# SF32LB55x register map
File version: 1.0
CPU: CM33 r0p1, little endian, MPU, FPU, 3 interrupt priority bits
Registers are 32-bit, read-write, reset 0x0 unless marked. A register's access mark holds for its fields unless they carry their own. Offsets are from the block's base; [hi:lo] are bit positions; {n}, {i} and the like mark numbered series.

## SDMMC1
Base 0x50004000
Same registers: SDMMC2 0x50005000
0x00 SAR — System Address/Argument2 Register
  [31:0] ADDR — This register contains the physical system memory address used for DMA transfers or the second argument for the Auto CMD23. (1) SDMA System Address This register contains the system memory address for a SDMA transfer. The SDMA transfer waits at the every boundary specified by BSR_SDMABDY. After SDMA has stopped, the next system address of the next contiguous data position cannot be read from this register but from NSAR. The Host Controller generates ISR_DMA Interrupt to request the Host Driver to update this register. The Host Driver sets the next system address of the next data position to this register. When the most upper byte of this register is written, the Host Controller restarts the SDMA transfer. (2) Argument 2 This register is used with the Auto CMD23 to set a 32-bit block count value to the argument of the CMD23 while executing Auto CMD23. If Auto CMD23 is used with ADMA, the full 32-bit block count value can be used. If Auto CMD23 is used without AMDA, the available block count value is limited by BSR_BCNT. 65535 blocks is the maximum value in this case.
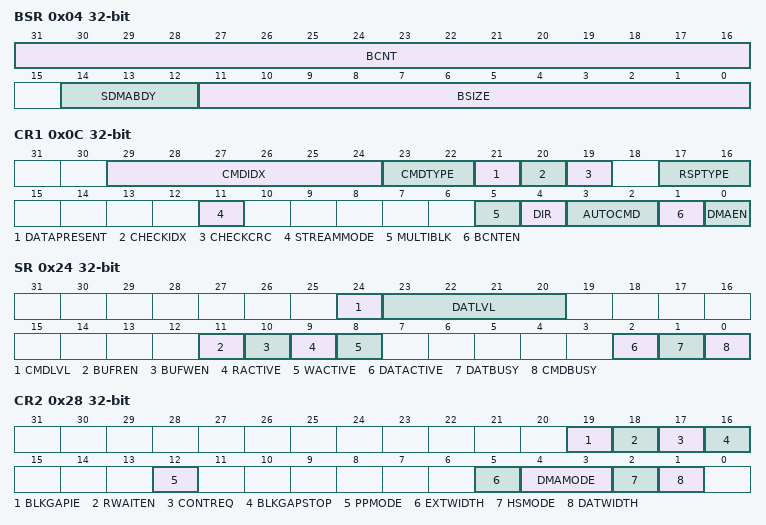
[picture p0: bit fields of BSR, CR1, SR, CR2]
0x04 BSR — Block Size Register
  [31:16] BCNT — Blocks Count For Current Transfer. This register is enabled when MULTIBLK is set to 1 and is valid only for multiple block transfers. Controller decrements the block count after each block transfer. Setting the block count to 0 results in no data blocks is transferred. This register should be accessed only when no transaction is executing (i.e., after transactions are stopped). During data transfer, read operations on this register may return an invalid value and write operations are ignored. When a suspend command is completed, the number of blocks yet to be transferred can be determined by reading this register. Before issuing a resume command, the Host Driver shall restore the previously saved block count. FFFFh 65535 blocks ... ... 0002h 2 blocks 0001h 1 block 0000h Stop Count
  [14:12] SDMABDY — Host SDMA Buffer Boundary. The large contiguous memory space may not be available in the virtual memory system. To perform long SDMA transfer, SDMA System Address register shall be updated at every system memory boundary during SDMA transfer. These bits specify the size of contiguous buffer in the system memory. The SDMA transfer shall wait at the every boundary specified by these fields and the Controller generates the ISR_DMA Interrupt to request the Host Driver to update the SDMA System Address register. At the end of transfer, the Controller may issue or may not issue ISR_DMA Interrupt. In particular, ISR_DMA Interrupt shall not be issued after ISR_TC Interrupt is issued. In case of this register is set to 0 (buffer size = 4K bytes), lower 12-bit of byte address points data in the contiguous buffer and the upper 20-bit points the location of the buffer in the system memory. The SDMA transfer stops when the Controller detects carry out of the address from bit 11 to 12. ADMA does not use this register. 000b 4K bytes (Detects A11 carry out) 001b 8K bytes (Detects A12 carry out) 010b 16K Bytes (Detects A13 carry out) 011b 32K Bytes (Detects A14 carry out) 100b 64K bytes (Detects A15 carry out) 101b 128K Bytes (Detects A16 carry out) 110b 256K Bytes (Detects A17 carry out) 111b 512K Bytes (Detects A18 carry out)
  [11:0] BSIZE — Transfer Block Size This register specifies the block size of data transfers such as CMD17, CMD18, CMD24, CMD25, and CMD53. Usually set to 512 for SD and eMMC access.
0x08 ARG1 — Argument 1
  [31:0] ARG — Command Argument 1 The SD command argument is specified as bit39-8 of Command-Format in the Physical Layer Specification.
0x0C CR1 — Control and Command Register 1
  [29:24] CMDIDX — Command Index These bits shall be set to the command number (CMD0-63, ACMD0-63) that is specified in bits 45-40 of the Command-Format in the Physical Layer Specification and SDIO Card Specification.
  [23:22] CMDTYPE — Command Type There are three types of special commands: Suspend, Resume and Abort. These bits shall be set to 00b for all other commands. (1) Suspend Command If the Suspend command succeeds, the Controller shall assume the SD Bus has been released and that it is possible to issue the next command, which uses the DAT line. The Controller shall de-assert Read Wait for read transactions and stop checking busy for write transactions. The interrupt cycle shall start, in 4-bit mode. If the Suspend command fails, the Controller shall maintain its current state, and the Host Driver shall restart the transfer by setting CR2_CONTREQ. (2) Resume Command The Host Driver re-starts the data transfer. The Controller shall check for busy before starting write transfers. (3) Abort Command If this command is set when executing a read transfer, the Controller shall stop reads to the buffer. If this command is set when executing a write transfer, the Controller shall stop driving the DAT line. After issuing the Abort command, the Host Driver should issue a software reset. 11b Abort CMD12, CMD52 for writing "I/O Abort" in CCCR 10b Resume CMD52 for writing "Function Select" in CCCR 01b Suspend CMD52 for writing "Bus Suspend" in CCCR 00b Normal Other commands
  [21] DATAPRESENT — Data Present Select This bit is set to 1 to indicate that data is present and shall be transferred using the DAT line. It is set to 0 for the following: (1) Commands using only CMD line (ex. CMD52). (2) Commands with no data transfer but using busy signal on DAT[0] line (R1b or R5b ex. CMD38) (3) Resume command
  [20] CHECKIDX — Command Index Check Enable If this bit is set to 1, the Controller shall check the Index field in the response to see if it has the same value as the command index. If it is not, it is reported as a Command Index Error. If this bit is set to 0, the Index field is not checked.
  [19] CHECKCRC — Command CRC Check Enable If this bit is set to 1, the Controller shall check the CRC field in the response. If an error is detected, it is reported as a Command CRC Error. If this bit is set to 0, the CRC field is not checked. The position of CRC field is determined according to the length of the response.
  [17:16] RSPTYPE — Response Type Select 00 No Response 01 Response Length 136 10 Response Length 48 11 Response Length 48 check Busy after
  [11] STREAMMODE — Stream Mode Enable The Host driver has to set this bit for MMC CMD11 / CMD20 Stream Read/Write Operations.
  [5] MULTIBLK — Multi / Single Block Select This bit is set when issuing multiple-block transfer commands using DAT line. For any other commands, this bit shall be set to 0. If this bit is 0, it is not necessary to set BSR_BCNT
  [4] DIR — Data Transfer Direction Select This bit defines the direction of DAT line data transfers. The bit is set to 1 to read data from the SD card to the Controller and it is set to 0 for all other commands. 1 Read (Card to Host) 0 Write (Host to Card)
  [3:2] AUTOCMD — Auto CMD Enable This field determines use of auto command functions. 00b Auto Command Disabled 01b Auto CMD12 Enabled 10b Auto CMD23 Enabled 11b Reserved There are two methods to stop Multiple-block read and write operation. (1) Auto CMD12 Enable When this field is set to 01b, the Controller issues CMD12 automatically when last block transfer is completed. Auto CMD12 error is indicated to CR4. The Host Driver shall not set this bit if the command does not require CMD12. (2) Auto CMD23 Enable When this bit field is set to 10b, the Controller issues a CMD23 automatically before issuing a command specified. The following conditions are required to use the Auto CMD23. A memory card that supports CMD23 (SCR[33]=1) If DMA is used, it shall be ADMA. Only when CMD18 or CMD25 is issued (Note, the Controller does not check command index.) Auto CMD23 can be used with or without ADMA. The Controller issues a CMD23 first and then issues a command specified by CR1. If response errors of CMD23 are detected, the second command is not issued. A CMD23 error is indicated in CR4. 32-bit block count value for CMD23 is set to SAR.
  [1] BCNTEN — Block Count Enable This bit is used to enable the Block Count register, which is only relevant for multiple block transfers. When this bit is 0, the Block Count register is disabled, which is useful in executing an infinite transfer. If ADMA data transfer is more than 65535 blocks, this bit shall be set to 0. In this case, data transfer length is designated by Descriptor Table.
  [0] DMAEN — DMA Enable This bit enables DMA functionality. SDMA or ADMA mode can be selected by CR2_DMAMODE.
0x10 RSP1 — Command Response 31~0
  [31:0] RSP — Command Response [31:0] The Response Field indicates bit positions of "Responses" defined in the Physical Layer Spec. Most responses with a length of 48 (R[47:0]) have 32 bits of the response data (R[39:8]) stored in RSP1. Responses of type R1b (Auto CMD12 responses) and R1 (Auto CMD23 response) have response data bits R[39:8] stored in RSP4. Responses with length 136 (R[135:0]) have 120 bits of the response data (R[127:8]) stored in RSP1~RSP4. To be able to read the response status efficiently, the Controller only stores part of the response data. This enables the Host Driver to read 32 bits of response data efficiently in one read cycle on a 32-bit bus system. Parts of the response, the Index field and the CRC, are checked by the Controller (as specified by CR1_CHECKIDX and the CR1_CHECKCRC) and generate an error interrupt if an error is detected. The bit range for the CRC check depends on the response length. If the response length is 48, the Controller shall check R[47:1], and if the response length is 136 the Controller shall check R[119:1]. Since the Controller may have a multiple block data DAT line transfer executing concurrently with a CMD_wo_DAT command, the Controller stores the Auto CMD12 response in RSP4. The CMD_wo_DAT response is stored in RSP1. This allows the Controller to avoid overwriting the Auto CMD12 response with the CMD_wo_DAT and vice versa. While executing Auto CMD23, the response of CMD23 is saved to RSP4 and the response of multiple-block read and write command is save to RSP1. The response error of CMD23 is indicated in CR4.
{0xC+4i} RSP{i} (i=2..4) — Command Response {32i-1}~{32i-32}
  [31:0] RSP — Command Response [{32i-1}:{32i-32}]
0x20 BUF — Buffer Data Port Register
  [31:0] DATA — Buffer Data The Controller buffer can be accessed through this 32-bit Data Port register.
0x24 SR — Present State Register
  [24] CMDLVL — CMD Line Signal Level This status is used to check the CMD line level to recover from errors, and for debugging.
  [23:20] DATLVL — DAT-DAT3 Line Signal Level This status is used to check the DAT line level to recover from errors, and for debugging. This is especially useful in detecting the busy signal level from DAT [0].
  [11] BUFREN — Buffer Read Enable This status is used for non-DMA read transfers. The Controller may implement multiple buffers to transfer data efficiently. This read only flag indicates that valid data exists in the host side buffer. If this bit is 1, readable data exists in the buffer. A change of this bit from 1 to 0 occurs when all the block data is read from the buffer. A change of this bit from 0 to 1 occurs when block data is ready in the buffer and generates ISR_BUFRRDY.
  [10] BUFWEN — Buffer Write Enable This status is used for non-DMA write transfers. The Controller can implement multiple buffers to transfer data efficiently. This read only flag indicates if space is available for write data. If this bit is 1, data can be written to the buffer. A change of this bit from 1 to 0 occurs when all the block data is written to the buffer. A change of this bit from 0 to 1 occurs when top of block data can be written to the buffer and generates ISR_BUFWRDY. The Controller should neither set Buffer Write Enable nor generate ISR_BUFWRDY after the last block data is written to the Buffer Data Port Register.
  [9] RACTIVE — Read Transfer Active This status is used for detecting completion of a read transfer. This bit is set to 1 for either of the following conditions: (1) After the end bit of the readcommand. (2) When read operation is restarted by writing 1 to CR2_CONTREQ. This bit is cleared to 0 for either of the following conditions: (1) When the last data block as specified by block length is transferred to the System. (2) In case of ADMA, end of read operation is designated by Descriptor Table. (3) When all valid data blocks in the Controller have been transferred to the System and no current block transfers are being sent as a result of CR2_BLKGAPSTOP being set to 1. A Transfer Complete interrupt is generated when this bit changes to 0.
  [8] WACTIVE — Write Transfer Active This status indicates a write transfer is active. If this bit is 0, it means no valid write data exists in the Controller. This bit is set in either of the following cases:  After the end bit of the write command.  When write operation is restarted by writing 1 to CR2_CONTREQ. This bit is cleared in either of the following cases:  After getting the CRC status of the last data block as specified by the transfer count (Single and Multiple) In case of ADMA, transfer count is designated by Descriptor Table.  After getting the CRC status of any block where data transmission is about to be stopped by CR2_BLKGAPSTOP. During a write transaction, ISR_BLKGAP is generated when this bit is changed to 0, as the result of CR2_BLKGAPSTOP begin set. This status is useful for the Host Driver in determining non DAT line commands can be issued during write busy.
  [2] DATACTIVE — DAT Line Active This bit indicates whether one of the DAT line on SD Bus is in use. (a) In the case of read transactions This status indicates whether a read transfer is executing on the SD Bus. Changing this value from 1 to 0 generates ISR_BLKGAP, as the result of CR2_BLKGAPSTOP being set. This bit shall be set in either of the following cases: (1) After the end bit of the read command. (2) When writing 1 to CR2_CONTREQ to restart a read transfer. This bit shall be cleared in either of the following cases (1) When the end bit of the last data block is sent from the SD Bus to the Controller. In case of ADMA, the last block is designated by the last transfer of Descriptor Table. (2) When a read transfer is stopped at the block gap initiated by CR2_BLKGAPSTOP. The Controller shall stop read operation at the start of the interrupt cycle of the next block gap by driving Read Wait or stopping SD clock. If the Read Wait signal is already driven (due to data buffer cannot receive data), the Controller can continue to stop read operation by driving the Read Wait signal. It is necessary to support Read Wait in order to use suspend / resume function. (b) In the case of write transactions This status indicates that a write transfer is executing on the SD Bus. Changing this value from 1 to 0 generate ISR_TC. This bit shall be set in either of the following cases: (1) After the end bit of the write command. (2) When writing 1 to CR2_CONTREQ to continue a write transfer. This bit shall be cleared in either of the following cases: (1) When the SD card releases write busy of the last data block. If SD card does not drive busy signal for 8 SD Clocks, the Controller shall consider the card drive "Not Busy". In case of ADMA, the last block is designated by the last transfer of Descriptor Table. (2) When the SD card releases write busy prior to waiting for write transfer as a result of CR2_BLKGAPSTOP. (c) Command with busy This status indicates whether a command indicates busy (ex. erase command for memory) is executing on the SD Bus. This bit is set after the end bit of the command with busy and cleared when busy is de-asserted. Changing this bit from 1 to 0 generate ISR_TC.
  [1] DATBUSY — Command Inhibit (DAT) This status bit is generated if either the DAT Line Active or the Read Transfer Active is set to 1. If this bit is 0, it indicates the Controller can issue the next SD Command. Commands with busy signal belong to Command Inhibit (DAT) (ex. R1b, R5b type). Changing from 1 to 0 generates ISR_TC interrupt. 1 Cannot issue command which uses the DAT line 0 Can issue command which uses the DAT line
  [0] CMDBUSY — Command Inhibit (CMD) If this bit is 0, it indicates the CMD line is not in use and the Controller can issue a SD Command using the CMD line. This bit is set immediately after CR1 is written. This bit is cleared when the command response is received. Auto CMD12 and Auto CMD23 consist of two responses. In this case, this bit is not cleared by the response of CMD12 or CMD23 but cleared by the response of a read/write command. Status issuing Auto CMD12 is not read from this bit. So if a command is issued during Auto CMD12 operation, Controller shall manage to issue two commands: CMD12 and a command set by CR1. Even if the DATBUSY is set to 1, commands using only the CMD line can be issued if this bit is 0. Changing from 1 to 0 generates ISR_CC Interrupt. If the Controller cannot issue the command because of a command conflict error or because of Command Not Issued By Auto CMD12 Error, this bit shall remain 1 and the Command Complete is not set. 1 Cannot issue command 0 Can issue command using only CMD line
0x28 CR2 — Control Register 2
  [19] BLKGAPIE — Interrupt At Block Gap This bit is valid only in 4-bit mode of the SDIO card and selects a sample point in the interrupt cycle. Setting to 1 enables interrupt detection at the block gap for a multiple block transfer. Setting to 0 disables interrupt detection during a multiple block transfer. If the SD card cannot signal an interrupt during a multiple block transfer, this bit should be set to 0. The Host Driver shall set this bit according to the CCCR of the SDIO card.
  [18] RWAITEN — Read Wait Control The read wait function is optional for SDIO cards. If the card supports read wait, set this bit to enable use of the read wait protocol to stop read data using the DAT2 line. Otherwise, the Controller has to stop the SD Clock to hold read data, which restricts commands generation. The Host Driver shall set this bit according to the CCCR of the SDIO card. If the card does not support read wait, this bit shall never be set to 1 otherwise DAT line conflict may occur. If this bit is set to 0, Suspend/Resume cannot be supported.
  [17] CONTREQ — Continue Request
  [16] BLKGAPSTOP — Stop At Block Gap request This bit is used to stop executing read and write transaction at the next block gap for non-DMA, SDMA and ADMA transfers. The Host Driver shall leave this bit set to 1 until the Transfer Complete is set to 1. Clearing both Stop At Block Gap Request and Continue Request shall not cause the transaction to restart. The Controller shall stop read transfer by using Read Wait or stopping SD clock. In case of write transfers in which the Host Driver writes data to the Buffer Data Port register, the Host Driver shall set this bit after all block data is written. If this bit is set to 1, the Host Driver shall not write data to BUF. 1 Stop 0 Transfer
  [12] PPMODE — CMD line output mode. Open drain mode should only be used when accessing eMMC device. 1 Push Pull Mode 0 Open Drain Mode
  [5] EXTWIDTH — Extended Data Transfer Width 1 8-bit Bus Width 0 Bus Width is Selected by DATAWIDTH
  [4:3] DMAMODE — DMA Select One of supported DMA modes can be selected. DMA mode is enabled by CR1_DMAEN. 00b SDMA 01b Reserved 10b ADMA 11b Reserved
  [2] HSMODE — Reserved for debug. Adjust output timing of CMD line and DAT lines.
  [1] DATWIDTH — Data Transfer Width This bit selects the data width of the Controller when EXTWIDTH is 0. The Host Driver shall set it to match the data width of the SD card. 1 4-bit mode 0 1-bit mode
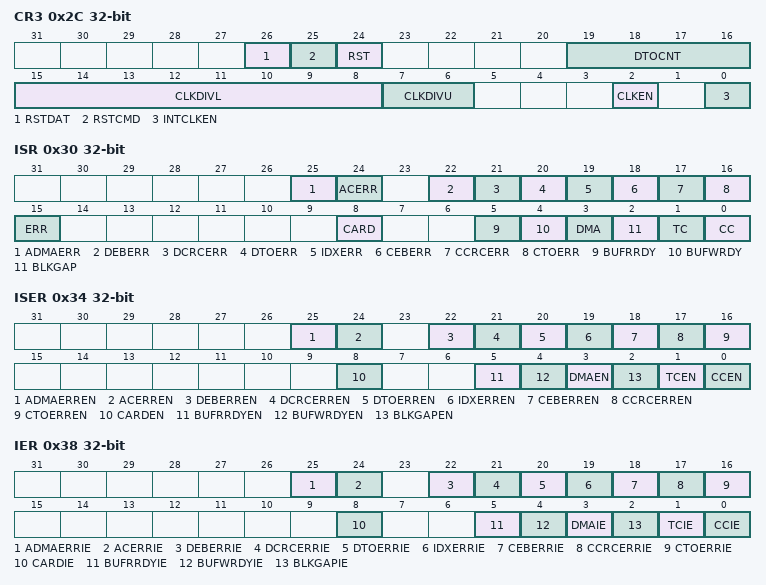
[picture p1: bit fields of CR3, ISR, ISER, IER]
0x2C CR3 — Control Register 3
  [26] RSTDAT — Software Reset For DAT Line Only part of data circuit is reset. DMA circuit is also reset. Will be cleared automatically. Because it takes some time to complete software reset, the SD Host Driver shall confirm that these bits are 0.
  [25] RSTCMD — Software Reset For CMD Line Only part of command circuit is reset. Will be cleared automatically. Because it takes some time to complete software reset, the SD Host Driver shall confirm that these bits are 0.
  [24] RST — This reset affects the entire Controller except for the card detection circuit. Register bits (except read-only bits) are cleared to 0. During its initialization, the Host Driver shall set this bit to 1 to reset the Controller. If this bit is set to 1, the host driver should issue reset command and reinitialize the SD card. Will be cleared automatically. Because it takes some time to complete software reset, the SD Host Driver shall confirm that these bits are 0.
  [19:16] DTOCNT — Data Timeout Counter Value This value determines the interval by which DAT line timeouts are detected. Timeout period is defined as: 1111b Reserved 1110b 4096*2^14 FCLK periods ............ ............ 0001b 4096*2^1 FCLK periods 0000b 4096*2 FCLK periods
  [15:8] CLKDIVL — CLK divider lower 8 bits 10-bit CLKDIV is {CLKDIVU,CLKDIVL}. If CLKDIV=0, CLK = FCLK. If CLKDIV!=0, CLK = FCLK/(2*CLKDIV). e.g. FCLK=192MHz, CLKDIV=240, then CLK frequency is 400KHz.
  [7:6] CLKDIVU — CLK divider upper 2 bits These bits expand clk divider to 10-bit.
  [2] CLKEN — SD Clock Enable 0: SD clock disabled 1: SD clock enabled
  [0] INTCLKEN — Internal Clock Enable 0: Internal clock disabled 1: Internal clock enabled
0x30 ISR — Interrupt State Register
  [25] ADMAERR — ADMA Error This bit is set when the Controller detects errors during ADMA based data transfer. The state of the ADMA at an error occurrence is saved in the AESR, In addition, the Controller generates this Interrupt when it detects invalid descriptor data (Valid=0). ADMA Error State in the ADMA Error Status indicates that an error occurs. The Host Driver may find that Valid bit is not set at the error descriptor.
  [24] ACERR — Auto CMD Error Auto CMD12 and Auto CMD23 use this error status. In case of Auto CMD12, this bit is set to 1, not only when the errors in Auto CMD12 occur but also when Auto CMD12 is not executed due to the previous command error.
  [22] DEBERR — Data End Bit Error Occurs either when detecting 0 at the end bit position of read data which uses the DAT line or at the end bit position of the CRC Status.
  [21] DCRCERR — Data CRC Error Occurs when detecting CRC error when transferring read data which uses the DAT line or when detecting the Write CRC status having a value of other than "010".
  [20] DTOERR — Data Timeout Error This bit is set when detecting one of following timeout conditions.  Busy timeout for R1b,R5b type  Busy timeout after Write CRC status  Write CRC Status timeout  Read Data timeout.
  [19] IDXERR — Command Index Error This bit is set if a Command Index error occurs in the command response.
  [18] CEBERR — Command End Bit Error This bit is set when detecting that the end bit of a command response is 0.
  [17] CCRCERR — Command CRC Error Command CRC Error is generated in two cases. If a response is returned and the Command Timeout Error is set to 0 (indicating no timeout), this bit is set to 1 when detecting a CRC error in the command response. The Controller detects a CMD line conflict by monitoring the CMD line when a command is issued. If the Controller drives the CMD line to 1 level, but detects 0 level on the CMD line at the next SD clock edge, then the Controller shall abort the command (Stop driving CMD line) and set this bit to 1. The Command Timeout Error shall also be set to 1 to distinguish CMD line conflict
  [16] CTOERR — Command Timeout Error This bit is set only if no response is returned within 64 SD clock cycles from the end bit of the command. If the Controller detects a CMD line conflict, in which case Command CRC Error shall also be set, this bit shall be set without waiting for 64 SD clock cycles because the command will be aborted by the Controller.
  [15] ERR — Error Interrupt If any error bit (bit16~bit31) of ISR are set, then this bit is set. Therefore the Host Driver can efficiently test for an error by checking this bit first. This bit is read only.
  [8] CARD — Card Interrupt Writing this bit to 1 does not clear this bit. It is cleared by resetting the SD card interrupt factor. In 4-bit mode, the card interrupt signal is sampled during the interrupt cycle, so there are some sample delays between the interrupt signal from the SD card and the interrupt to the Host System. When this status has been set and the Host Driver needs to start this interrupt service, ISER_CARDEN may be set to 0 in order to clear the card interrupt statuses latched in the Controller and to stop driving the interrupt signal to the Host System. After completion of the card interrupt service (It should reset interrupt factors in the SD card and the interrupt signal may not be asserted), set ISER_CARDEN to 1 and start sampling the interrupt signal again.
  [5] BUFRRDY — Buffer Read Ready This status is set if the Buffer Read Enable changes from 0 to 1. Refer to SR_BUFREN register. 1 Ready to read buffer 0 Not ready to read buffer
  [4] BUFWRDY — Buffer Write Ready This status is set if the Buffer Write Enable changes from 0 to 1. Refer to SR_BUFWEN register. 1 Ready to write buffer 0 Not ready to write buffer
  [3] DMA — DMA Interrupt This status is set if the Controller detects the Host SDMA Buffer boundary during transfer. Refer to BSR_SDMABDY. In case of ADMA, by setting INT field in the descriptor table, Controller generates this interrupt. This interrupt shall not be generated after the Transfer Complete.
  [2] BLKGAP — Block Gap Event If CR2_BLKGAPSTOP is set, this bit is set when both a read / write transaction is stopped at a block gap. If CR2_BLKGAPSTOP is not set to 1, this bit is not set to 1. (1) In the case of a Read Transaction This bit is set at the falling edge of the DAT Line Active Status (When the transaction is stopped at SD Bus timing. The Read Wait shall be supported in order to use this function. (2) Case of Write Transaction This bit is set at the falling edge of Write Transfer Active Status (After getting CRC status at SD Bus timing). 1 Transaction stopped at block 0 No Block Gap Event
  [1] TC — Transfer Complete This bit is set when a read / write transfer and a command with busy is completed. (1) In the case of a Read Transaction This bit is set at the falling edge of Read Transfer Active Status. This interrupt is generated in two cases. The first is when a data transfer is completed as specified by data length (After the last data has been read to the Host System). The second is when data has stopped at the block gap and completed the data transfer by setting CR2_BLKGAPSTOP (After valid data has been read to the Host System). (2) In the case of a Write Transaction This bit is set at the falling edge of the DAT Line Active Status. This interrupt is generated in two cases. The first is when the last data is written to the SD card as specified by data length and the busy signal released. The second is when data transfers are stopped at the block gap by setting CR2_BLKGAPSTOP and data transfers completed. (After valid data is written to the SD card and the busy signal released). (3) In the case of a command with busy This bit is set when busy is de-asserted. Refer to SR_DATACTIVE and SR_CMDBUSY. Transfer Complete has higher priority than Data Timeout Error. If both bits are set to 1, execution of a command can be considered to be completed.
  [0] CC — Command Complete This bit is set when get the end bit of the command response. Auto CMD12 and Auto CMD23 consist of two responses. Command Complete is not generated by the response of CMD12 or CMD23 but generated by the response of a read/write command. Command Timeout Error has higher priority than Command Complete. If both bits are set to 1, it can be considered that the response was not received correctly.
0x34 ISER — Interrupt Status Enable Register
  [25] ADMAERREN — ADMA Error Status Enable
  [24] ACERREN — Auto CMD Error Status Enable
  [22] DEBERREN — Data End Bit Error Status Enable
  [21] DCRCERREN — Data CRC Error Status Enable
  [20] DTOERREN — Data Timeout Error Status Enable
  [19] IDXERREN — Command Index Error Status Enable
  [18] CEBERREN — Command End Bit Error Status Enable
  [17] CCRCERREN — Command CRC Error Status Enable
  [16] CTOERREN — Command Timeout Error Status Enable
  [8] CARDEN — Card Interrupt Status Enable If this bit is set to 0, the Controller shall clear interrupt request to the System. The Card Interrupt detection is stopped when this bit is cleared and restarted when this bit is set to 1. The Host Driver may clear the Card Interrupt Status Enable before servicing the Card Interrupt and may set this bit again after all interrupt requests from the card are cleared to prevent inadvertent interrupts.
  [5] BUFRRDYEN — Buffer Read Ready Status Enable
  [4] BUFWRDYEN — Buffer Write Ready Status Enable
  [3] DMAEN — DMA Interrupt Status Enable
  [2] BLKGAPEN — Block Gap Event Status Enable
  [1] TCEN — Transfer Complete Status Enable
  [0] CCEN — Command Complete Status Enable
0x38 IER — Interrupt Enable Register
  [25] ADMAERRIE — ADMA Error Interrupt Enable
  [24] ACERRIE — Auto CMD Error Interrupt Enable
  [22] DEBERRIE — Data End Bit Error Interrupt Enable
  [21] DCRCERRIE — Data CRC Error Interrupt Enable
  [20] DTOERRIE — Data Timeout Error Interrupt Enable
  [19] IDXERRIE — Command Index Error Interrupt Enable
  [18] CEBERRIE — Command End Bit Error Interrupt Enable
  [17] CCRCERRIE — Command CRC Error Interrupt Enable
  [16] CTOERRIE — Command Timeout Error Interrupt Enable
  [8] CARDIE — Card Interrupt Interrupt Enable If this bit is set to 0, the Controller shall clear interrupt request to the System. The Card Interrupt detection is stopped when this bit is cleared and restarted when this bit is set to 1. The Host Driver may clear the Card Interrupt Status Enable before servicing the Card Interrupt and may set this bit again after all interrupt requests from the card are cleared to prevent inadvertent interrupts.
  [5] BUFRRDYIE — Buffer Read Ready Interrupt Enable
  [4] BUFWRDYIE — Buffer Write Ready Interrupt Enable
  [3] DMAIE — DMA Interrupt Interrupt Enable
  [2] BLKGAPIE — Block Gap Event Interrupt Enable
  [1] TCIE — Transfer Complete Interrupt Enable
  [0] CCIE — Command Complete Interrupt Enable
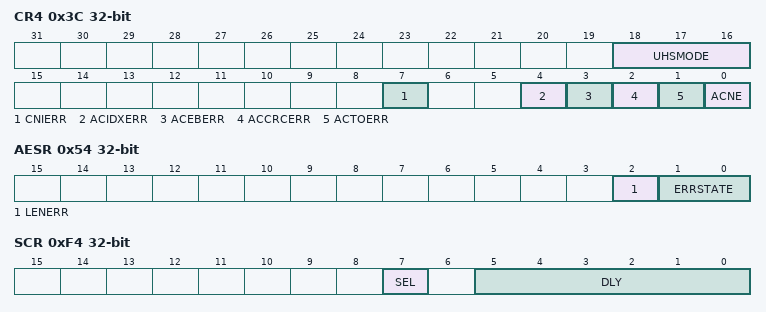
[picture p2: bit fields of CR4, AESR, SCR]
0x3C CR4 — Control Register 4
  [18:16] UHSMODE — UHS Mode Select 100b DDR others SDR
  [7] CNIERR — Command Not Issued By Auto CMD12 Error Setting this bit to 1 means CMD_wo_DAT is not executed due to an Auto CMD12 Error in this register. This bit is set to 0 when Auto CMD Error is generated by Auto CMD23. 1 Not Issued 0 No Error
  [4] ACIDXERR — Auto CMD Index Error This bit is set if the Command Index error occurs in response to a command
  [3] ACEBERR — Auto CMD End Bit Error This bit is set when detecting that the end bit of command response is 0.
  [2] ACCRCERR — Auto CMD CRC Error This bit is set when detecting a CRC error in the command response.
  [1] ACTOERR — Auto CMD Timeout Error This bit is set if no response is returned within 64 SDCLK cycles from the end bit of command. If this bit is set to1, the other error status bits are meaningless.
  [0] ACNE — Auto CMD12 Not Executed If memory multiple block data transfer is not started due to command error, this bit is not set because it is not necessary to issue Auto CMD12. Setting this bit to 1 means the Controller cannot issue Auto CMD12 to stop memory multiple block data transfer due to some error. If this bit is set to 1, other error status bits are meaningless. This bit is set to 0 when Auto CMD Error is generated by Auto CMD23. 1 Not Executed 0 Executed
0x54 AESR — ADMA Error Status Register
  [2] LENERR — ADMA Length Mismatch Error This error occurs in the following 2 cases. (1) While CR1_BCNTEN being set, the total data length specified by the Descriptor table is different from that specified by the Block Count and Block Length. (2) Total data length cannot be divided by the block length.
  [1:0] ERRSTATE — ADMA Error State This field indicates the state of ADMA when error is occurred during ADMA data transfer. This field never indicates "10" because ADMA never stops in this state. 00 ST_STOP (Stop DMA) Points next of the error descriptor 01 ST_FDS (Fetch Descriptor) Points the error descriptor 10 Never set this state (Not used) 11 ST_TFR (Transfer Data) Points the next of the error descriptor
0x58 ASAR — ADMA System Address Register
  [31:0] ADDR — ADMA System Address This register holds byte address of executing command of the Descriptor table. At the start of ADMA, the Host Driver shall set start address of the Descriptor table. The ADMA increments this register address, which points to next line, when every fetching a Descriptor line. When the ADMA Error Interrupt is generated, this register shall hold valid Descriptor address depending on the ADMA state. The Host Driver shall program Descriptor Table on 32-bit boundary and set 32-bit boundary address to this register. Lower 2-bit of this register is ignored and assumes it to be 00b.
0x5C NSAR — Next System Address Register
  [31:0] ADDR — This register contains next physical system memory address used for SDMA transfer. When the Host Controller stops a SDMA transfer, this register shall point to the system address of the next contiguous data position. It can be accessed only if no transaction is executing (i.e., after a transaction has stopped). Read operations during transfers may return an invalid value. After SDMA has stopped, the next system address of the next contiguous data position can be read from this register.
0xEC ABSR — AHB Burst Size Register
  [6:0] BSIZE — AHB Master Burst Size Register AHB Master performs Burst operations as per this register. 0 – Disabled 1 – Enabled Bit 00 INCR4 Bit 01 INCR8 Bit 02 INCR16 Bit 03 INCR Bit 04 WRAP4 Bit 05 WRAP8 Bit 06 WRAP16
0xF4 SCR — Sampling Clock Register
  [7] SEL — select sampling clock source (delay line input) 0: use internal clock 1: use loopback clock
  [5:0] DLY — Stages of delay line for sampling clock
